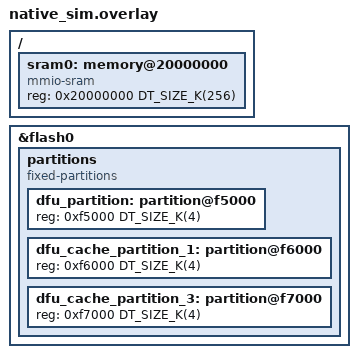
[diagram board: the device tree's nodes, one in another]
/*
 * Copyright (c) 2023 Nordic Semiconductor ASA
 *
 * SPDX-License-Identifier: LicenseRef-Nordic-5-Clause
 */

&flash0 {
	partitions {
		compatible = "fixed-partitions";
		#address-cells = < 0x1 >;
		#size-cells = < 0x1 >;

		dfu_partition: partition@f5000 {
			reg = < 0xf5000 DT_SIZE_K(4) >;
		};

		dfu_cache_partition_1: partition@f6000 {
			reg = <0xf6000 DT_SIZE_K(4)>;
		};

		dfu_cache_partition_3: partition@f7000 {
			reg = <0xf7000 DT_SIZE_K(4)>;
		};
	};
};

/ {
	sram0: memory@20000000 {
		compatible = "mmio-sram";
		reg = <0x20000000 DT_SIZE_K(256)>;
	};
};
